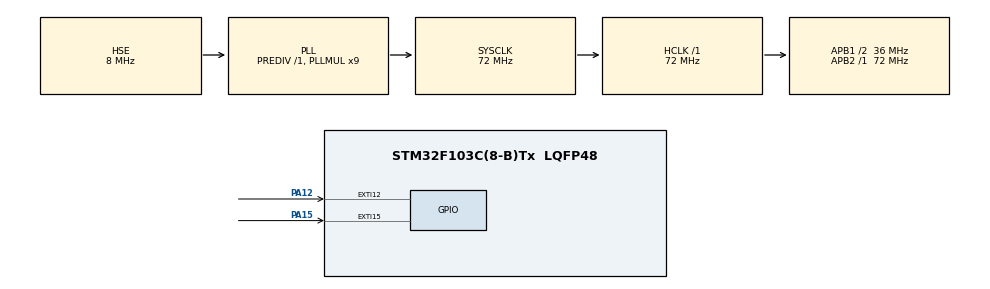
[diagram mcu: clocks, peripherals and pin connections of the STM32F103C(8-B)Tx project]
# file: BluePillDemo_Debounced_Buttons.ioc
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Mcu.Family=STM32F1
Mcu.Name=STM32F103C(8-B)Tx
Mcu.Package=LQFP48
NVIC.EXTI15_10_IRQn=true\:0\:0\:false\:false\:true\:true\:true
NVIC.PriorityGroup=NVIC_PRIORITYGROUP_4
NVIC.TIM4_IRQn=true\:0\:0\:false\:false\:true\:true\:true
PA12.GPIO_PuPd=GPIO_PULLUP
PA12.Signal=GPXTI12
PA13.Mode=Serial_Wire
PA13.Signal=SYS_JTMS-SWDIO
PA14.Mode=Serial_Wire
PA14.Signal=SYS_JTCK-SWCLK
PA15.GPIO_PuPd=GPIO_PULLUP
PA15.Signal=GPXTI15
PC14-OSC32_IN.Mode=LSE-External-Oscillator
PC14-OSC32_IN.Signal=RCC_OSC32_IN
PC15-OSC32_OUT.Mode=LSE-External-Oscillator
PC15-OSC32_OUT.Signal=RCC_OSC32_OUT
PD0-OSC_IN.Mode=HSE-External-Oscillator
PD0-OSC_IN.Signal=RCC_OSC_IN
PD1-OSC_OUT.Mode=HSE-External-Oscillator
PD1-OSC_OUT.Signal=RCC_OSC_OUT
ProjectManager.HeapSize=0x200
ProjectManager.StackSize=0x400
ProjectManager.TargetToolchain=STM32CubeIDE
RCC.AHBFreq_Value=72000000
RCC.APB1CLKDivider=RCC_HCLK_DIV2
RCC.APB1Freq_Value=36000000
RCC.APB1TimFreq_Value=72000000
RCC.APB2Freq_Value=72000000
RCC.APB2TimFreq_Value=72000000
RCC.HCLKFreq_Value=72000000
RCC.PLLMUL=RCC_PLL_MUL9
RCC.PLLSourceVirtual=RCC_PLLSOURCE_HSE
RCC.SYSCLKFreq_VALUE=72000000
RCC.SYSCLKSource=RCC_SYSCLKSOURCE_PLLCLK
RCC.USBFreq_Value=72000000
TIM4.Period=0x1000
TIM4.Prescaler=48
VP_TIM4_VS_ClockSourceINT.Mode=Internal
board=custom

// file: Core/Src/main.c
/* USER CODE BEGIN Header */
/**
  ******************************************************************************
  * @file           : main.c
  * @brief          : Main program body
  ******************************************************************************
  * @attention
  *
  * <h2><center>&copy; Copyright (c) 2020 STMicroelectronics.
  * All rights reserved.</center></h2>
  *
  * This software component is licensed by ST under BSD 3-Clause license,
  * the "License"; You may not use this file except in compliance with the
  * License. You may obtain a copy of the License at:
  *                        opensource.org/licenses/BSD-3-Clause
  *
  ******************************************************************************
  */
/* USER CODE END Header */

#include "main.h"

/* USER CODE BEGIN Includes */

#include <stdbool.h>

/* USER CODE END Includes */

/* USER CODE BEGIN PM */

#define TOP_BUTTON					1U
#define BOTTOM_BUTTON				2U
#define BUTTON_LONG_PRESS_OFFSET	2U
#define TOP_BUTTON_LONG				(TOP_BUTTON + BUTTON_LONG_PRESS_OFFSET)
#define BOTTOM_BUTTON_LONG			(BOTTOM_BUTTON + BUTTON_LONG_PRESS_OFFSET)

/* USER CODE END PM */

TIM_HandleTypeDef htim4;

/* USER CODE BEGIN PV */

static volatile uint8_t buttons_value = 0U;

/* USER CODE END PV */

void SystemClock_Config(void);
static void MX_GPIO_Init(void);
static void MX_TIM4_Init(void);

/* USER CODE BEGIN 0 */

void enable_exti_line_interrupt(uint32_t line, bool enabled)
{
	EXTI_ConfigTypeDef extiConfig;
	EXTI_HandleTypeDef handleTypeDef = {0};

	handleTypeDef.Line = line;
	HAL_EXTI_GetConfigLine(&handleTypeDef, &extiConfig);
	if (enabled)
	{
		extiConfig.Mode = EXTI_MODE_INTERRUPT;
	}
	else
	{
		extiConfig.Mode = EXTI_MODE_NONE;
	}
	HAL_EXTI_SetConfigLine(&handleTypeDef, &extiConfig);
}

void HAL_TIM_PeriodElapsedCallback(TIM_HandleTypeDef *htim)
{
	static uint8_t button_event;
	static uint32_t button_time_counter;

	if (htim == &htim4)
	{
		if (button_time_counter == 10UL)
		{
			if (HAL_GPIO_ReadPin(GPIOA, GPIO_PIN_12) == GPIO_PIN_SET)
			{
				button_event = TOP_BUTTON;
				button_time_counter = 24UL;
			}
			else if (HAL_GPIO_ReadPin(GPIOA, GPIO_PIN_15) == GPIO_PIN_SET)
			{
				button_event = BOTTOM_BUTTON;
				button_time_counter = 24UL;
			}
			else
			{
				// kill timer and switch exti interrupts back on
				HAL_TIM_Base_Stop_IT(&htim4);
				enable_exti_line_interrupt(12U, true);
				enable_exti_line_interrupt(15U, true);
				button_time_counter = 0UL;
			}
		}
		else if (button_time_counter >= 28UL && button_time_counter < 124UL)
		{
			if (HAL_GPIO_ReadPin(GPIOA, GPIO_PIN_12) == GPIO_PIN_RESET && HAL_GPIO_ReadPin(GPIOA, GPIO_PIN_15) == GPIO_PIN_RESET)
			{
				buttons_value = button_event;
				button_time_counter = 200UL;
			}
		}
		else if (button_time_counter == 124UL)
		{
			buttons_value = button_event + BUTTON_LONG_PRESS_OFFSET;
			button_time_counter = 200UL;
		}
		else if (button_time_counter >= 210UL)
		{
			if (HAL_GPIO_ReadPin(GPIOA, GPIO_PIN_12) == GPIO_PIN_RESET && HAL_GPIO_ReadPin(GPIOA, GPIO_PIN_15) == GPIO_PIN_RESET)
			{
				// kill timer and switch exti interrupts back on
				HAL_TIM_Base_Stop_IT(&htim4);
				enable_exti_line_interrupt(12U, true);
				enable_exti_line_interrupt(15U, true);
				button_time_counter = 0UL;
			}
		}

	    button_time_counter++;
	}
}

void HAL_GPIO_EXTI_Callback(uint16_t GPIO_Pin)
{
	if (GPIO_Pin == GPIO_PIN_15)
	{
		// switch off exti interrupts on line 15
		enable_exti_line_interrupt(15U, false);
		HAL_TIM_Base_Start_IT(&htim4);
	}
	else if (GPIO_Pin == GPIO_PIN_12)
	{
		// switch off exti interrupts on line 12
		enable_exti_line_interrupt(12U, false);
		HAL_TIM_Base_Start_IT(&htim4);
	}
}

/* USER CODE END 0 */

int main(void)
{

  /* MCU Configuration--------------------------------------------------------*/

  /* Reset of all peripherals, Initializes the Flash interface and the Systick. */
  HAL_Init();

  /* Configure the system clock */
  SystemClock_Config();

  /* Initialize all configured peripherals */
  MX_GPIO_Init();
  MX_TIM4_Init();

  /* Infinite loop */
  while (1)
  {

  }
}

void SystemClock_Config(void)
{
  RCC_OscInitTypeDef RCC_OscInitStruct = {0};
  RCC_ClkInitTypeDef RCC_ClkInitStruct = {0};

  /** Initializes the CPU, AHB and APB busses clocks
  */
  RCC_OscInitStruct.OscillatorType = RCC_OSCILLATORTYPE_HSE;
  RCC_OscInitStruct.HSEState = RCC_HSE_ON;
  RCC_OscInitStruct.HSEPredivValue = RCC_HSE_PREDIV_DIV1;
  RCC_OscInitStruct.HSIState = RCC_HSI_ON;
  RCC_OscInitStruct.PLL.PLLState = RCC_PLL_ON;
  RCC_OscInitStruct.PLL.PLLSource = RCC_PLLSOURCE_HSE;
  RCC_OscInitStruct.PLL.PLLMUL = RCC_PLL_MUL9;
  if (HAL_RCC_OscConfig(&RCC_OscInitStruct) != HAL_OK)
  {
    Error_Handler();
  }
  /** Initializes the CPU, AHB and APB busses clocks
  */
  RCC_ClkInitStruct.ClockType = RCC_CLOCKTYPE_HCLK|RCC_CLOCKTYPE_SYSCLK
                              |RCC_CLOCKTYPE_PCLK1|RCC_CLOCKTYPE_PCLK2;
  RCC_ClkInitStruct.SYSCLKSource = RCC_SYSCLKSOURCE_PLLCLK;
  RCC_ClkInitStruct.AHBCLKDivider = RCC_SYSCLK_DIV1;
  RCC_ClkInitStruct.APB1CLKDivider = RCC_HCLK_DIV2;
  RCC_ClkInitStruct.APB2CLKDivider = RCC_HCLK_DIV1;

  if (HAL_RCC_ClockConfig(&RCC_ClkInitStruct, FLASH_LATENCY_2) != HAL_OK)
  {
    Error_Handler();
  }
}

static void MX_TIM4_Init(void)
{

  TIM_ClockConfigTypeDef sClockSourceConfig = {0};
  TIM_MasterConfigTypeDef sMasterConfig = {0};

  htim4.Instance = TIM4;
  htim4.Init.Prescaler = 48;
  htim4.Init.CounterMode = TIM_COUNTERMODE_UP;
  htim4.Init.Period = 0x1000;
  htim4.Init.ClockDivision = TIM_CLOCKDIVISION_DIV1;
  htim4.Init.AutoReloadPreload = TIM_AUTORELOAD_PRELOAD_DISABLE;
  if (HAL_TIM_Base_Init(&htim4) != HAL_OK)
  {
    Error_Handler();
  }
  sClockSourceConfig.ClockSource = TIM_CLOCKSOURCE_INTERNAL;
  if (HAL_TIM_ConfigClockSource(&htim4, &sClockSourceConfig) != HAL_OK)
  {
    Error_Handler();
  }
  sMasterConfig.MasterOutputTrigger = TIM_TRGO_RESET;
  sMasterConfig.MasterSlaveMode = TIM_MASTERSLAVEMODE_DISABLE;
  if (HAL_TIMEx_MasterConfigSynchronization(&htim4, &sMasterConfig) != HAL_OK)
  {
    Error_Handler();
  }

}

static void MX_GPIO_Init(void)
{
  GPIO_InitTypeDef GPIO_InitStruct = {0};

  /* GPIO Ports Clock Enable */
  __HAL_RCC_GPIOC_CLK_ENABLE();
  __HAL_RCC_GPIOD_CLK_ENABLE();
  __HAL_RCC_GPIOA_CLK_ENABLE();

  /*Configure GPIO pins : PA12 PA15 */
  GPIO_InitStruct.Pin = GPIO_PIN_12|GPIO_PIN_15;
  GPIO_InitStruct.Mode = GPIO_MODE_IT_RISING;
  GPIO_InitStruct.Pull = GPIO_PULLUP;
  HAL_GPIO_Init(GPIOA, &GPIO_InitStruct);

  /* EXTI interrupt init*/
  HAL_NVIC_SetPriority(EXTI15_10_IRQn, 0, 0);
  HAL_NVIC_EnableIRQ(EXTI15_10_IRQn);

}

void Error_Handler(void)
{
}

/************************ (C) COPYRIGHT STMicroelectronics *****END OF FILE****/
